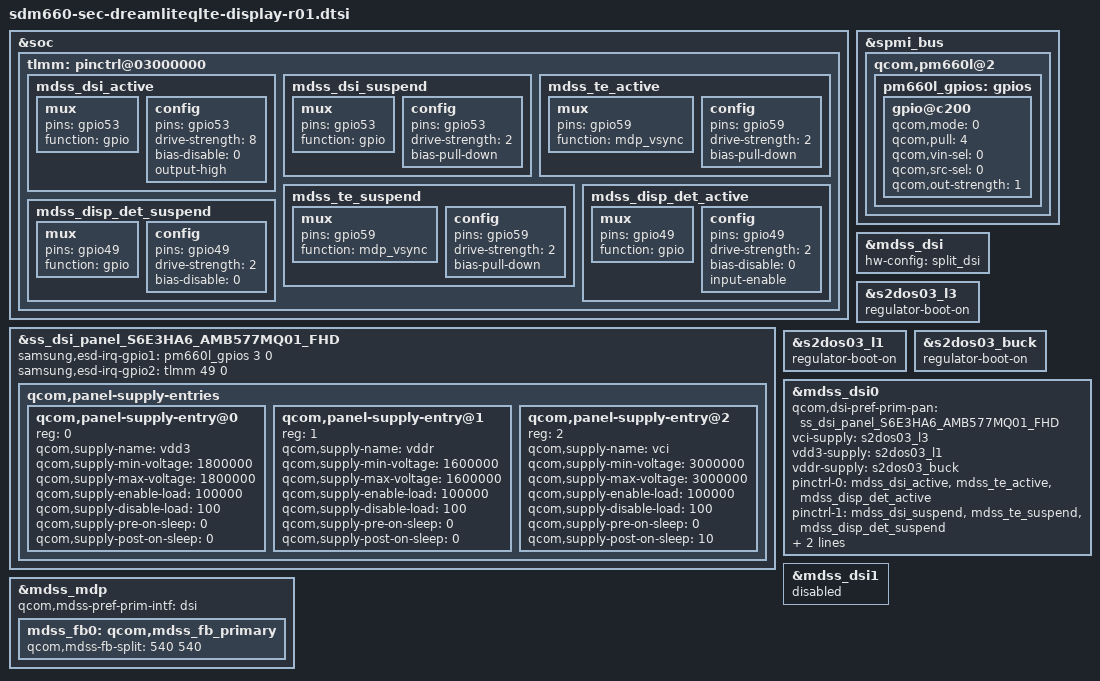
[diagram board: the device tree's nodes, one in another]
/* Copyright (c) 2016, The Linux Foundation. All rights reserved.
 *
 * This program is free software; you can redistribute it and/or modify
 * it under the terms of the GNU General Public License version 2 and
 * only version 2 as published by the Free Software Foundation.
 *
 * This program is distributed in the hope that it will be useful,
 * but WITHOUT ANY WARRANTY; without even the implied warranty of
 * MERCHANTABILITY or FITNESS FOR A PARTICULAR PURPOSE.  See the
 * GNU General Public License for more details.
 */

#include "../../../../drivers/video/fbdev/msm/samsung/S6E3HA6_AMB577MQ01/dsi_panel_S6E3HA6_AMB577MQ01_wqhd_octa_cmd.dtsi"
#include "../../../../drivers/video/fbdev/msm/samsung/PBA_BOOTING/dsi_panel_PBA_BOOTING_fhd_video.dtsi"

/*
 * SOC Setting (TLMM Pin Control & SPI Setting)
 */

&soc {
	tlmm: pinctrl@03000000 {
		mdss_dsi_active: mdss_dsi_active {
			mux {
				pins = "gpio53"; /* rst */
				function = "gpio";
			};

			config {
				pins = "gpio53";
				drive-strength = <8>; /* 8 mA */
				bias-disable = <0>; /* no pull */
				output-high;
			};
		};

		mdss_dsi_suspend: mdss_dsi_suspend {
			mux {
				pins = "gpio53"; /* rst */
				function = "gpio";
			};

			config {
				pins = "gpio53";
				drive-strength = <2>; /* 2 mA */
				bias-pull-down; /* pull down */
			};
		};

		mdss_te_active: mdss_te_active {
			mux {
				pins = "gpio59";
				function = "mdp_vsync";
			};
			config {
				pins = "gpio59";
				drive-strength = <2>; /* 8 mA */
				bias-pull-down; /* pull down*/
			};
		};

		mdss_te_suspend: mdss_te_suspend {
			mux {
				pins = "gpio59";
				function = "mdp_vsync";
			};
			config {
				pins = "gpio59";
				drive-strength = <2>; /* 2 mA */
				bias-pull-down; /* pull down */
			};
		};

		mdss_disp_det_active: mdss_disp_det_active {
			mux {
				pins = "gpio49";
				function = "gpio";
			};
			config {
				pins = "gpio49";
				drive-strength = <2>; /* 8 mA */
				bias-disable = <0>; /* no pull */
				input-enable;
			};
		};

		mdss_disp_det_suspend: mdss_disp_det_suspend {
			mux {
				pins = "gpio49";
				function = "gpio";
			};
			config {
				pins = "gpio49";
				drive-strength = <2>; /* 2 mA */
				bias-disable = <0>; /* no pull */
			};
		};

	};
};

&spmi_bus {
	qcom,pm660l@2 {
		pm660l_gpios: gpios {

			gpio@c200 {			/* gpio 3, FG_ERR */
				qcom,mode = <0>;
				qcom,pull = <4>;
				qcom,vin-sel = <0>;
				qcom,src-sel = <0>;
				qcom,out-strength = <1>;
				status = "okay";
			};
		};
	};
};

&ss_dsi_panel_S6E3HA6_AMB577MQ01_FHD {
/*	qcom,mdss-dsi-bl-pmic-control-type = "bl_ctrl_dcs"; */
/*	qcom,mdss-dsi-bl-min-level = <1>; */
/*	qcom,mdss-dsi-bl-max-level = <365>; */

	samsung,esd-irq-gpio1 = <&pm660l_gpios 3 0>;
	samsung,esd-irq-gpio2 = <&tlmm 49 0>;

	qcom,panel-supply-entries {
        #address-cells = <1>;
        #size-cells = <0>;

        qcom,panel-supply-entry@0 {
            reg = <0>;
            qcom,supply-name = "vdd3";
            qcom,supply-min-voltage = <1800000>;
            qcom,supply-max-voltage = <1800000>;
            qcom,supply-enable-load = <100000>;
            qcom,supply-disable-load = <100>;
            qcom,supply-pre-on-sleep = <0>; /* unit is ms*/
            qcom,supply-post-on-sleep = <0>;
        };

        qcom,panel-supply-entry@1 {
            reg = <1>;
            qcom,supply-name = "vddr";
            qcom,supply-min-voltage = <1600000>;
            qcom,supply-max-voltage = <1600000>;
            qcom,supply-enable-load = <100000>;
            qcom,supply-disable-load = <100>;
            qcom,supply-pre-on-sleep = <0>; /* unit is ms*/
            qcom,supply-post-on-sleep = <0>;
        };

        qcom,panel-supply-entry@2 {
            reg = <2>;
            qcom,supply-name = "vci";
            qcom,supply-min-voltage = <3000000>;
            qcom,supply-max-voltage = <3000000>;
            qcom,supply-enable-load = <100000>;
            qcom,supply-disable-load = <100>;
            qcom,supply-pre-on-sleep = <0>; /* unit is ms*/
            qcom,supply-post-on-sleep = <10>;
        };
    };
/*
	qcom,mdss-dsi-panel-timings-phy-v2 = [
		24 1f 08 09 05 03 04 a0
		24 1f 08 09 05 03 04 a0
		24 1f 08 09 05 03 04 a0
		24 1f 08 09 05 03 04 a0
		24 1B 08 09 05 03 04 a0
	];
*/
};

&mdss_dsi {
	hw-config = "split_dsi"; /* DSC */
};

/*
 * LDOs for LCD Driver
 */

&s2dos03_l3 {
	regulator-boot-on;
};

&s2dos03_l1 {
	regulator-boot-on;
};

&s2dos03_buck {
	regulator-boot-on;
};

&mdss_dsi0 {
	qcom,dsi-pref-prim-pan = <&ss_dsi_panel_S6E3HA6_AMB577MQ01_FHD>;

	/*  Panel Power
	 *   vci -> s2mpb02_l17(needed to define here)
	 *   vdd3 -> pm8994_lvs2(needed to define here)
	 *   vddr -> s2mpb02_b1(needed to define here)
	 */
	vci-supply = <&s2dos03_l3>; /* 3.0V */
	vdd3-supply = <&s2dos03_l1>; /* 1.8V */
	vddr-supply = <&s2dos03_buck>; /* 1.6V */

	pinctrl-names = "mdss_default", "mdss_sleep";
	pinctrl-0 = <&mdss_dsi_active &mdss_te_active &mdss_disp_det_active>;
	pinctrl-1 = <&mdss_dsi_suspend &mdss_te_suspend &mdss_disp_det_suspend>;

	qcom,platform-reset-gpio = <&tlmm 53 0>;
	qcom,platform-te-gpio = <&tlmm 59 0>;
};

&mdss_dsi1 {
	status = "disabled";
};

&mdss_mdp {
    qcom,mdss-pref-prim-intf = "dsi";
    mdss_fb0: qcom,mdss_fb_primary {
        qcom,mdss-fb-split = <540 540>;
    };
};
